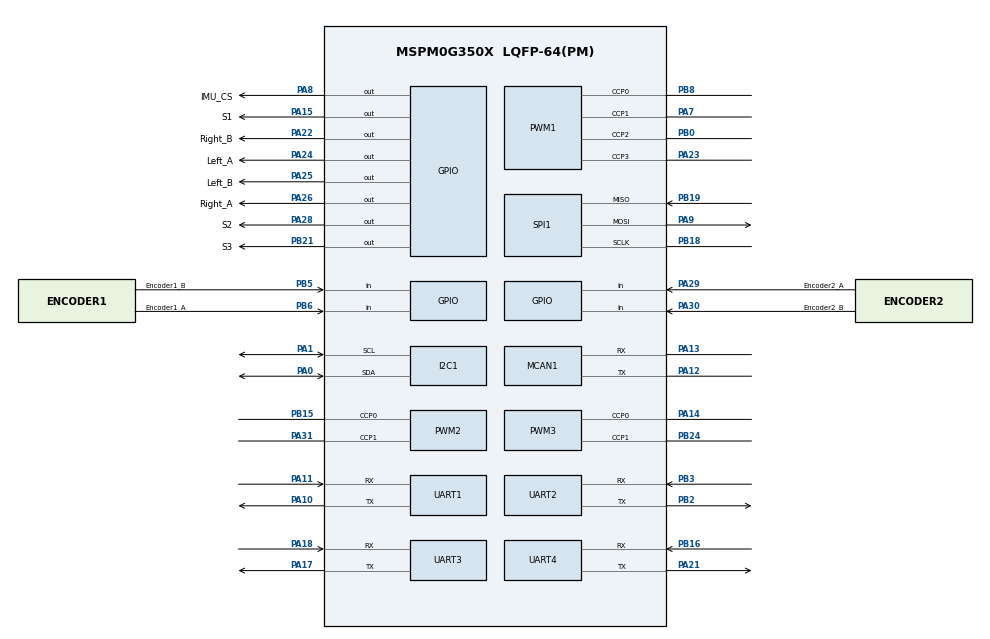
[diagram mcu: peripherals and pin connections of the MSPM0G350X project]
/**
 * @cliArgs --device "MSPM0G350X" --part "Default" --package "LQFP-64(PM)" --product "mspm0_sdk@2.02.00.05"
 * @versions {"tool":"1.21.1+3772"}
 */

/**
 * Import the modules used in this configuration.
 */
const ADC12   = scripting.addModule("/ti/driverlib/ADC12", {}, false);
const ADC121  = ADC12.addInstance();
const DMA     = scripting.addModule("/ti/driverlib/DMA");
const GPIO    = scripting.addModule("/ti/driverlib/GPIO", {}, false);
const GPIO1   = GPIO.addInstance();
const GPIO2   = GPIO.addInstance();
const GPIO3   = GPIO.addInstance();
const GPIO4   = GPIO.addInstance();
const GPIO5   = GPIO.addInstance();
const I2C     = scripting.addModule("/ti/driverlib/I2C", {}, false);
const I2C1    = I2C.addInstance();
const MCAN    = scripting.addModule("/ti/driverlib/MCAN", {}, false);
const MCAN1   = MCAN.addInstance();
const PWM     = scripting.addModule("/ti/driverlib/PWM", {}, false);
const PWM1    = PWM.addInstance();
const PWM2    = PWM.addInstance();
const PWM3    = PWM.addInstance();
const SPI     = scripting.addModule("/ti/driverlib/SPI", {}, false);
const SPI1    = SPI.addInstance();
const SYSCTL  = scripting.addModule("/ti/driverlib/SYSCTL");
const SYSTICK = scripting.addModule("/ti/driverlib/SYSTICK");
const TIMER   = scripting.addModule("/ti/driverlib/TIMER", {}, false);
const TIMER1  = TIMER.addInstance();
const TIMER2  = TIMER.addInstance();
const UART    = scripting.addModule("/ti/driverlib/UART", {}, false);
const UART1   = UART.addInstance();
const UART2   = UART.addInstance();
const UART3   = UART.addInstance();
const UART4   = UART.addInstance();

/**
 * Write custom configuration values to the imported modules.
 */
const divider7       = system.clockTree["PLL_PDIV"];
divider7.divideValue = 4;

const divider9       = system.clockTree["UDIV"];
divider9.divideValue = 2;

const gate7  = system.clockTree["MFCLKGATE"];
gate7.enable = true;

const multiplier2         = system.clockTree["PLL_QDIV"];
multiplier2.multiplyValue = 20;

const mux2       = system.clockTree["CANCLKMUX"];
mux2.inputSelect = "CANCLKMUX_PLLCLK1_OUT";

const mux8       = system.clockTree["HSCLKMUX"];
mux8.inputSelect = "HSCLKMUX_SYSPLL0";

const pinFunction4       = system.clockTree["HFXT"];
pinFunction4.inputFreq   = 40;
pinFunction4.HFXTStartup = 10;
pinFunction4.enable      = true;

ADC121.$name                             = "ADC_track";
ADC121.sampClkDiv                        = "DL_ADC12_CLOCK_DIVIDE_8";
ADC121.repeatMode                        = true;
ADC121.peripheral.adcPin0.$assign        = "PA27";
ADC121.adcPin0Config.hideOutputInversion = scripting.forceWrite(false);
ADC121.adcPin0Config.$name               = "ti_driverlib_gpio_GPIOPinGeneric2";

const Board = scripting.addModule("/ti/driverlib/Board", {}, false);

DMA.associatedChannels.create(1);
DMA.associatedChannels[0].$name              = "DMA_Track";
DMA.associatedChannels[0].peripheral.$assign = "DMA_CH0";

GPIO1.$name                          = "MOTOR_DIR";
GPIO1.associatedPins.create(4);
GPIO1.associatedPins[0].assignedPort = "PORTA";
GPIO1.associatedPins[0].assignedPin  = "24";
GPIO1.associatedPins[0].$name        = "Left_A";
GPIO1.associatedPins[0].initialValue = "SET";
GPIO1.associatedPins[0].pin.$assign  = "PA24";
GPIO1.associatedPins[1].$name        = "Left_B";
GPIO1.associatedPins[1].initialValue = "SET";
GPIO1.associatedPins[1].pin.$assign  = "PA25";
GPIO1.associatedPins[2].$name        = "Right_A";
GPIO1.associatedPins[2].initialValue = "SET";
GPIO1.associatedPins[2].pin.$assign  = "PA26";
GPIO1.associatedPins[3].$name        = "Right_B";
GPIO1.associatedPins[3].initialValue = "SET";
GPIO1.associatedPins[3].pin.$assign  = "PA22";

GPIO2.$name                          = "TRACK";
GPIO2.associatedPins.create(3);
GPIO2.associatedPins[0].initialValue = "SET";
GPIO2.associatedPins[0].$name        = "S1";
GPIO2.associatedPins[0].pin.$assign  = "PA15";
GPIO2.associatedPins[1].initialValue = "SET";
GPIO2.associatedPins[1].$name        = "S2";
GPIO2.associatedPins[1].pin.$assign  = "PA28";
GPIO2.associatedPins[2].$name        = "S3";
GPIO2.associatedPins[2].pin.$assign  = "PB21";

GPIO3.$name                               = "Encoder";
GPIO3.associatedPins.create(4);
GPIO3.associatedPins[0].direction         = "INPUT";
GPIO3.associatedPins[0].interruptEn       = true;
GPIO3.associatedPins[0].polarity          = "RISE";
GPIO3.associatedPins[0].$name             = "Encoder1_A";
GPIO3.associatedPins[0].interruptPriority = "0";
GPIO3.associatedPins[0].pin.$assign       = "PB6";
GPIO3.associatedPins[1].direction         = "INPUT";
GPIO3.associatedPins[1].interruptEn       = true;
GPIO3.associatedPins[1].polarity          = "RISE";
GPIO3.associatedPins[1].$name             = "Encoder1_B";
GPIO3.associatedPins[1].interruptPriority = "0";
GPIO3.associatedPins[1].pin.$assign       = "PB5";
GPIO3.associatedPins[2].$name             = "Encoder2_A";
GPIO3.associatedPins[2].direction         = "INPUT";
GPIO3.associatedPins[2].interruptEn       = true;
GPIO3.associatedPins[2].polarity          = "RISE";
GPIO3.associatedPins[2].interruptPriority = "0";
GPIO3.associatedPins[2].pin.$assign       = "PA29";
GPIO3.associatedPins[3].$name             = "Encoder2_B";
GPIO3.associatedPins[3].direction         = "INPUT";
GPIO3.associatedPins[3].interruptEn       = true;
GPIO3.associatedPins[3].polarity          = "RISE";
GPIO3.associatedPins[3].interruptPriority = "0";
GPIO3.associatedPins[3].pin.$assign       = "PA30";

GPIO4.$name                          = "IMU";
GPIO4.associatedPins[0].initialValue = "SET";
GPIO4.associatedPins[0].$name        = "IMU_CS";
GPIO4.associatedPins[0].assignedPort = "PORTA";
GPIO4.associatedPins[0].assignedPin  = "8";
GPIO4.associatedPins[0].pin.$assign  = "PA8";

GPIO5.$name                          = "Beep";
GPIO5.associatedPins[0].$name        = "buzzer";
GPIO5.associatedPins[0].assignedPort = "PORTB";
GPIO5.associatedPins[0].assignedPin  = "12";

I2C1.$name                     = "I2C_0";
I2C1.peripheral.$assign        = "I2C0";
I2C1.peripheral.sdaPin.$assign = "PA0";
I2C1.peripheral.sclPin.$assign = "PA1";
I2C1.sdaPinConfig.$name        = "ti_driverlib_gpio_GPIOPinGeneric3";
I2C1.sclPinConfig.$name        = "ti_driverlib_gpio_GPIOPinGeneric4";

MCAN1.$name                    = "MCAN0";
MCAN1.peripheral.$assign       = "CANFD0";
MCAN1.peripheral.rxPin.$assign = "PA13";
MCAN1.peripheral.txPin.$assign = "PA12";
MCAN1.txPinConfig.$name        = "ti_driverlib_gpio_GPIOPinGeneric19";
MCAN1.rxPinConfig.$name        = "ti_driverlib_gpio_GPIOPinGeneric20";

PWM1.timerStartTimer                    = true;
PWM1.pwmMode                            = "EDGE_ALIGN_UP";
PWM1.$name                              = "PWM_Motor";
PWM1.timerCount                         = 10000;
PWM1.ccIndex                            = [0,1,2,3];
PWM1.clockPrescale                      = 20;
PWM1.peripheral.$assign                 = "TIMA0";
PWM1.peripheral.ccp0Pin.$assign         = "PB8";
PWM1.peripheral.ccp1Pin.$assign         = "PA7";
PWM1.peripheral.ccp2Pin.$assign         = "PB0";
PWM1.peripheral.ccp3Pin.$assign         = "PA23";
PWM1.PWM_CHANNEL_0.$name                = "ti_driverlib_pwm_PWMTimerCC0";
PWM1.PWM_CHANNEL_1.$name                = "ti_driverlib_pwm_PWMTimerCC1";
PWM1.ccp0PinConfig.direction            = scripting.forceWrite("OUTPUT");
PWM1.ccp0PinConfig.hideOutputInversion  = scripting.forceWrite(false);
PWM1.ccp0PinConfig.onlyInternalResistor = scripting.forceWrite(false);
PWM1.ccp0PinConfig.passedPeripheralType = scripting.forceWrite("Digital");
PWM1.ccp0PinConfig.$name                = "ti_driverlib_gpio_GPIOPinGeneric17";
PWM1.ccp1PinConfig.direction            = scripting.forceWrite("OUTPUT");
PWM1.ccp1PinConfig.hideOutputInversion  = scripting.forceWrite(false);
PWM1.ccp1PinConfig.onlyInternalResistor = scripting.forceWrite(false);
PWM1.ccp1PinConfig.passedPeripheralType = scripting.forceWrite("Digital");
PWM1.ccp1PinConfig.$name                = "ti_driverlib_gpio_GPIOPinGeneric8";
PWM1.PWM_CHANNEL_2.$name                = "ti_driverlib_pwm_PWMTimerCC2";
PWM1.PWM_CHANNEL_3.$name                = "ti_driverlib_pwm_PWMTimerCC3";
PWM1.ccp2PinConfig.$name                = "ti_driverlib_gpio_GPIOPinGeneric18";
PWM1.ccp3PinConfig.$name                = "ti_driverlib_gpio_GPIOPinGeneric14";

PWM2.$name                              = "PWM_0";
PWM2.pwmMode                            = "EDGE_ALIGN_UP";
PWM2.timerCount                         = 10000;
PWM2.peripheral.$assign                 = "TIMG7";
PWM2.peripheral.ccp0Pin.$assign         = "PB15";
PWM2.peripheral.ccp1Pin.$assign         = "PA31";
PWM2.PWM_CHANNEL_0.$name                = "ti_driverlib_pwm_PWMTimerCC4";
PWM2.PWM_CHANNEL_1.$name                = "ti_driverlib_pwm_PWMTimerCC5";
PWM2.ccp0PinConfig.direction            = scripting.forceWrite("OUTPUT");
PWM2.ccp0PinConfig.hideOutputInversion  = scripting.forceWrite(false);
PWM2.ccp0PinConfig.onlyInternalResistor = scripting.forceWrite(false);
PWM2.ccp0PinConfig.passedPeripheralType = scripting.forceWrite("Digital");
PWM2.ccp0PinConfig.$name                = "ti_driverlib_gpio_GPIOPinGeneric21";
PWM2.ccp1PinConfig.direction            = scripting.forceWrite("OUTPUT");
PWM2.ccp1PinConfig.hideOutputInversion  = scripting.forceWrite(false);
PWM2.ccp1PinConfig.onlyInternalResistor = scripting.forceWrite(false);
PWM2.ccp1PinConfig.passedPeripheralType = scripting.forceWrite("Digital");
PWM2.ccp1PinConfig.$name                = "ti_driverlib_gpio_GPIOPinGeneric22";

PWM3.$name                              = "PWM_1";
PWM3.pwmMode                            = "EDGE_ALIGN_UP";
PWM3.timerCount                         = 10000;
PWM3.peripheral.$assign                 = "TIMG12";
PWM3.peripheral.ccp0Pin.$assign         = "PA14";
PWM3.peripheral.ccp1Pin.$assign         = "PB24";
PWM3.PWM_CHANNEL_0.$name                = "ti_driverlib_pwm_PWMTimerCC6";
PWM3.PWM_CHANNEL_1.$name                = "ti_driverlib_pwm_PWMTimerCC7";
PWM3.ccp0PinConfig.direction            = scripting.forceWrite("OUTPUT");
PWM3.ccp0PinConfig.hideOutputInversion  = scripting.forceWrite(false);
PWM3.ccp0PinConfig.onlyInternalResistor = scripting.forceWrite(false);
PWM3.ccp0PinConfig.passedPeripheralType = scripting.forceWrite("Digital");
PWM3.ccp0PinConfig.$name                = "ti_driverlib_gpio_GPIOPinGeneric23";
PWM3.ccp1PinConfig.direction            = scripting.forceWrite("OUTPUT");
PWM3.ccp1PinConfig.hideOutputInversion  = scripting.forceWrite(false);
PWM3.ccp1PinConfig.onlyInternalResistor = scripting.forceWrite(false);
PWM3.ccp1PinConfig.passedPeripheralType = scripting.forceWrite("Digital");
PWM3.ccp1PinConfig.$name                = "ti_driverlib_gpio_GPIOPinGeneric24";

SPI1.$name                              = "SPI_IMU";
SPI1.enableDMAEvent1                    = false;
SPI1.enableDMAEvent2                    = false;
SPI1.targetBitRate                      = 5000000;
SPI1.peripheral.sclkPin.$assign         = "PB18";
SPI1.peripheral.mosiPin.$assign         = "PA9";
SPI1.peripheral.misoPin.$assign         = "PB19";
SPI1.sclkPinConfig.$name                = "ti_driverlib_gpio_GPIOPinGeneric11";
SPI1.sclkPinConfig.direction            = scripting.forceWrite("OUTPUT");
SPI1.sclkPinConfig.onlyInternalResistor = scripting.forceWrite(false);
SPI1.sclkPinConfig.passedPeripheralType = scripting.forceWrite("Digital");
SPI1.mosiPinConfig.$name                = "ti_driverlib_gpio_GPIOPinGeneric12";
SPI1.mosiPinConfig.direction            = scripting.forceWrite("OUTPUT");
SPI1.mosiPinConfig.hideOutputInversion  = scripting.forceWrite(false);
SPI1.mosiPinConfig.onlyInternalResistor = scripting.forceWrite(false);
SPI1.mosiPinConfig.passedPeripheralType = scripting.forceWrite("Digital");
SPI1.misoPinConfig.$name                = "ti_driverlib_gpio_GPIOPinGeneric13";
SPI1.misoPinConfig.onlyInternalResistor = scripting.forceWrite(false);
SPI1.misoPinConfig.passedPeripheralType = scripting.forceWrite("Digital");
SPI1.cs0PinConfig.direction             = scripting.forceWrite("OUTPUT");
SPI1.cs0PinConfig.hideOutputInversion   = scripting.forceWrite(false);
SPI1.cs0PinConfig.onlyInternalResistor  = scripting.forceWrite(false);
SPI1.cs0PinConfig.passedPeripheralType  = scripting.forceWrite("Digital");
SPI1.cs0PinConfig.$name                 = "ti_driverlib_gpio_GPIOPinGeneric9";

SYSCTL.forceDefaultClkConfig = true;
SYSCTL.clockTreeEn           = true;

SYSTICK.periodEnable      = true;
SYSTICK.period            = 32000;
SYSTICK.interruptEnable   = true;
SYSTICK.interruptPriority = "0";
SYSTICK.systickEnable     = true;

TIMER1.$name            = "TIMER_0";
TIMER1.timerClkDiv      = 8;
TIMER1.timerClkPrescale = 100;
TIMER1.timerMode        = "PERIODIC_UP";
TIMER1.timerStartTimer  = true;
TIMER1.interrupts       = ["LOAD"];
TIMER1.timerPeriod      = "1ms";

TIMER2.$name            = "TIMER_1";
TIMER2.timerMode        = "PERIODIC_UP";
TIMER2.timerPeriod      = "10 ms";
TIMER2.timerClkDiv      = 8;
TIMER2.timerClkPrescale = 20;
TIMER2.timerStartTimer  = true;
TIMER2.interrupts       = ["LOAD"];

UART1.enabledInterrupts                = ["RX"];
UART1.targetBaudRate                   = 115200;
UART1.$name                            = "UART_debug";
UART1.peripheral.$assign               = "UART0";
UART1.peripheral.rxPin.$assign         = "PA11";
UART1.peripheral.txPin.$assign         = "PA10";
UART1.txPinConfig.direction            = scripting.forceWrite("OUTPUT");
UART1.txPinConfig.hideOutputInversion  = scripting.forceWrite(false);
UART1.txPinConfig.onlyInternalResistor = scripting.forceWrite(false);
UART1.txPinConfig.passedPeripheralType = scripting.forceWrite("Digital");
UART1.txPinConfig.$name                = "ti_driverlib_gpio_GPIOPinGeneric0";
UART1.rxPinConfig.hideOutputInversion  = scripting.forceWrite(false);
UART1.rxPinConfig.onlyInternalResistor = scripting.forceWrite(false);
UART1.rxPinConfig.passedPeripheralType = scripting.forceWrite("Digital");
UART1.rxPinConfig.$name                = "ti_driverlib_gpio_GPIOPinGeneric1";

UART2.enabledInterrupts                = ["RX"];
UART2.$name                            = "UART_vision";
UART2.peripheral.rxPin.$assign         = "PB3";
UART2.peripheral.txPin.$assign         = "PB2";
UART2.txPinConfig.direction            = scripting.forceWrite("OUTPUT");
UART2.txPinConfig.hideOutputInversion  = scripting.forceWrite(false);
UART2.txPinConfig.onlyInternalResistor = scripting.forceWrite(false);
UART2.txPinConfig.passedPeripheralType = scripting.forceWrite("Digital");
UART2.txPinConfig.$name                = "ti_driverlib_gpio_GPIOPinGeneric5";
UART2.rxPinConfig.hideOutputInversion  = scripting.forceWrite(false);
UART2.rxPinConfig.onlyInternalResistor = scripting.forceWrite(false);
UART2.rxPinConfig.passedPeripheralType = scripting.forceWrite("Digital");
UART2.rxPinConfig.$name                = "ti_driverlib_gpio_GPIOPinGeneric6";

UART3.enabledInterrupts                = ["RX"];
UART3.$name                            = "UART_display";
UART3.peripheral.rxPin.$assign         = "PA18";
UART3.peripheral.txPin.$assign         = "PA17";
UART3.txPinConfig.direction            = scripting.forceWrite("OUTPUT");
UART3.txPinConfig.hideOutputInversion  = scripting.forceWrite(false);
UART3.txPinConfig.onlyInternalResistor = scripting.forceWrite(false);
UART3.txPinConfig.passedPeripheralType = scripting.forceWrite("Digital");
UART3.txPinConfig.$name                = "ti_driverlib_gpio_GPIOPinGeneric15";
UART3.rxPinConfig.hideOutputInversion  = scripting.forceWrite(false);
UART3.rxPinConfig.onlyInternalResistor = scripting.forceWrite(false);
UART3.rxPinConfig.passedPeripheralType = scripting.forceWrite("Digital");
UART3.rxPinConfig.$name                = "ti_driverlib_gpio_GPIOPinGeneric16";

UART4.targetBaudRate                   = 115200;
UART4.enabledInterrupts                = ["RX"];
UART4.$name                            = "UART_wired";
UART4.peripheral.$assign               = "UART2";
UART4.peripheral.rxPin.$assign         = "PB16";
UART4.peripheral.txPin.$assign         = "PA21";
UART4.txPinConfig.direction            = scripting.forceWrite("OUTPUT");
UART4.txPinConfig.hideOutputInversion  = scripting.forceWrite(false);
UART4.txPinConfig.onlyInternalResistor = scripting.forceWrite(false);
UART4.txPinConfig.passedPeripheralType = scripting.forceWrite("Digital");
UART4.txPinConfig.$name                = "ti_driverlib_gpio_GPIOPinGeneric7";
UART4.rxPinConfig.hideOutputInversion  = scripting.forceWrite(false);
UART4.rxPinConfig.onlyInternalResistor = scripting.forceWrite(false);
UART4.rxPinConfig.passedPeripheralType = scripting.forceWrite("Digital");
UART4.rxPinConfig.$name                = "ti_driverlib_gpio_GPIOPinGeneric10";

/**
 * Pinmux solution for unlocked pins/peripherals. This ensures that minor changes to the automatic solver in a future
 * version of the tool will not impact the pinmux you originally saw.  These lines can be completely deleted in order to
 * re-solve from scratch.
 */
pinFunction4.peripheral.$suggestSolution           = "SYSCTL";
pinFunction4.peripheral.hfxInPin.$suggestSolution  = "PA5";
pinFunction4.peripheral.hfxOutPin.$suggestSolution = "PA6";
ADC121.peripheral.$suggestSolution                 = "ADC0";
Board.peripheral.$suggestSolution                  = "DEBUGSS";
Board.peripheral.swclkPin.$suggestSolution         = "PA20";
Board.peripheral.swdioPin.$suggestSolution         = "PA19";
GPIO5.associatedPins[0].pin.$suggestSolution       = "PB12";
SPI1.peripheral.$suggestSolution                   = "SPI0";
SPI1.peripheral.cs0Pin.$suggestSolution            = "PA2";
TIMER1.peripheral.$suggestSolution                 = "TIMG0";
TIMER2.peripheral.$suggestSolution                 = "TIMA1";
UART2.peripheral.$suggestSolution                  = "UART3";
UART3.peripheral.$suggestSolution                  = "UART1";
